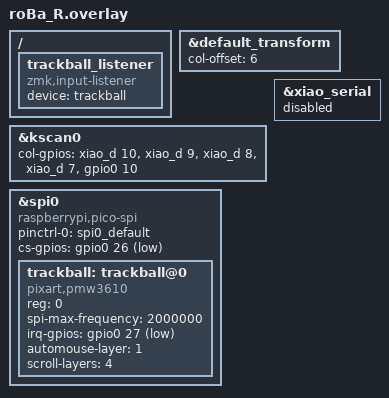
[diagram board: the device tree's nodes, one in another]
#include "roBa.dtsi"
#include <dt-bindings/pinctrl/rpi-pico-rp2040-pinctrl.h>

&default_transform {
    col-offset = <6>;
};

&kscan0 {
        col-gpios
            = <&xiao_d 10 GPIO_ACTIVE_HIGH>
            , <&xiao_d 9 GPIO_ACTIVE_HIGH> 
            , <&xiao_d 8 GPIO_ACTIVE_HIGH> 
            , <&xiao_d 7 GPIO_ACTIVE_HIGH> 
            , <&gpio0 10 GPIO_ACTIVE_HIGH>
            ;
};

/ {
    trackball_listener {
        compatible = "zmk,input-listener";
        device = <&trackball>;

    };
};



&xiao_serial { status = "disabled"; };

&spi0 {
    status = "okay";
    compatible = "raspberrypi,pico-spi";
    pinctrl-0 = <&spi0_default>;
    pinctrl-names = "default";

    /* CS=D0(=GPIO26) にした例。配線に合わせて変更OK */
    cs-gpios = <&gpio0 26 GPIO_ACTIVE_LOW>;

    trackball: trackball@0 {
        status = "okay";
        compatible = "pixart,pmw3610";
        reg = <0>;
        spi-max-frequency = <2000000>;
        /* IRQ=D1(=GPIO27) にした例 */
        irq-gpios = <&gpio0 27 (GPIO_ACTIVE_LOW | GPIO_PULL_UP)>;
        automouse-layer = <1>;
        scroll-layers = <4>;
    };
};


